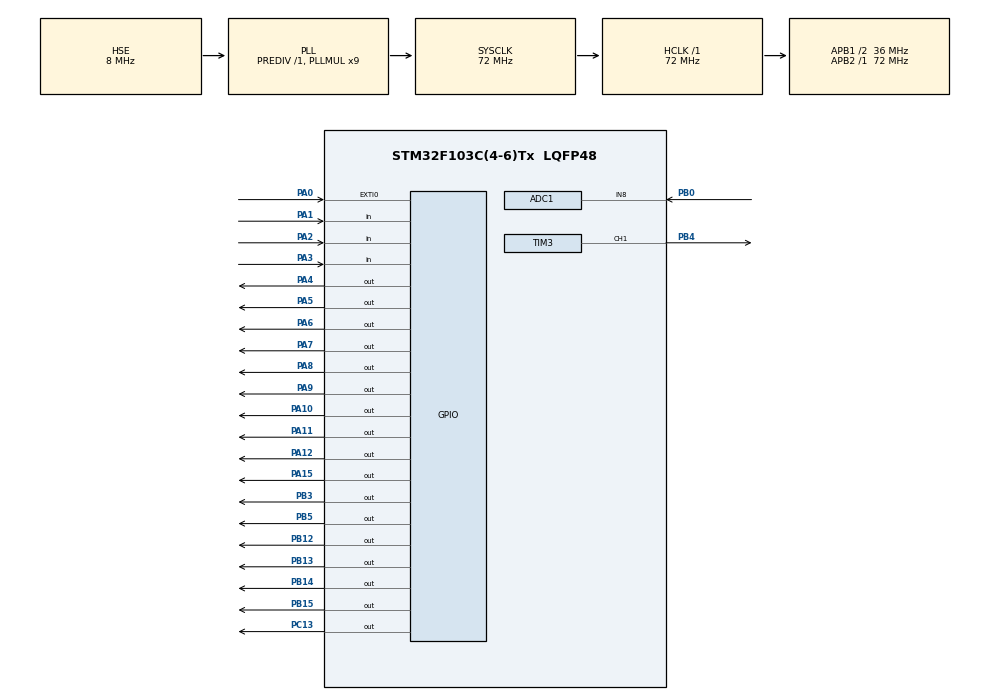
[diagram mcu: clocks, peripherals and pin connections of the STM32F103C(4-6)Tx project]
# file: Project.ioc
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ADC1.Channel-3\#ChannelRegularConversion=ADC_CHANNEL_8
ADC1.NbrOfConversionFlag=1
ADC1.Rank-3\#ChannelRegularConversion=1
ADC1.SamplingTime-3\#ChannelRegularConversion=ADC_SAMPLETIME_1CYCLE_5
ADC1.master=1
Mcu.Family=STM32F1
Mcu.Name=STM32F103C(4-6)Tx
Mcu.Package=LQFP48
NVIC.EXTI0_IRQn=true\:0\:0\:false\:false\:true\:true\:true
NVIC.PriorityGroup=NVIC_PRIORITYGROUP_4
NVIC.TIM1_UP_IRQn=true\:0\:0\:false\:false\:true\:true\:true
NVIC.TIM2_IRQn=true\:0\:0\:false\:false\:true\:true\:true
PA0-WKUP.GPIO_PuPd=GPIO_PULLUP
PA0-WKUP.Signal=GPXTI0
PA1.GPIO_PuPd=GPIO_PULLUP
PA1.Signal=GPIO_Input
PA10.Signal=GPIO_Output
PA11.Signal=GPIO_Output
PA12.Signal=GPIO_Output
PA13.Mode=Serial_Wire
PA13.Signal=SYS_JTMS-SWDIO
PA14.Mode=Serial_Wire
PA14.Signal=SYS_JTCK-SWCLK
PA15.Signal=GPIO_Output
PA2.GPIO_PuPd=GPIO_PULLUP
PA2.Signal=GPIO_Input
PA3.GPIO_PuPd=GPIO_PULLUP
PA3.Signal=GPIO_Input
PA4.GPIO_PuPd=GPIO_NOPULL
PA4.Signal=GPIO_Output
PA5.Signal=GPIO_Output
PA6.Signal=GPIO_Output
PA7.Signal=GPIO_Output
PA8.Signal=GPIO_Output
PA9.Signal=GPIO_Output
PB0.Signal=ADCx_IN8
PB12.Signal=GPIO_Output
PB13.Signal=GPIO_Output
PB14.Signal=GPIO_Output
PB15.Signal=GPIO_Output
PB3.Signal=GPIO_Output
PB4.Signal=S_TIM3_CH1
PB5.Signal=GPIO_Output
PC13-TAMPER-RTC.Signal=GPIO_Output
PD0-OSC_IN.Mode=HSE-External-Oscillator
PD0-OSC_IN.Signal=RCC_OSC_IN
PD1-OSC_OUT.Mode=HSE-External-Oscillator
PD1-OSC_OUT.Signal=RCC_OSC_OUT
ProjectManager.HeapSize=0x2000
ProjectManager.StackSize=0x2000
ProjectManager.TargetToolchain=EWARM V8.32
RCC.ADCPresc=RCC_ADCPCLK2_DIV6
RCC.AHBFreq_Value=72000000
RCC.APB1CLKDivider=RCC_HCLK_DIV2
RCC.APB1Freq_Value=36000000
RCC.APB1TimFreq_Value=72000000
RCC.APB2Freq_Value=72000000
RCC.APB2TimFreq_Value=72000000
RCC.HCLKFreq_Value=72000000
RCC.PLLMUL=RCC_PLL_MUL9
RCC.PLLSourceVirtual=RCC_PLLSOURCE_HSE
RCC.RCC_MCOSource=RCC_MCO1SOURCE_HSE
RCC.SYSCLKFreq_VALUE=72000000
RCC.SYSCLKSource=RCC_SYSCLKSOURCE_PLLCLK
RCC.USBFreq_Value=72000000
SH.ADCx_IN8.0=ADC1_IN8,IN8
SH.S_TIM3_CH1.0=TIM3_CH1,PWM Generation1 CH1
TIM1.Period=9
TIM1.Prescaler=7199
TIM2.Period=9
TIM2.Prescaler=7199
TIM3.Channel-PWM\ Generation1\ CH1=TIM_CHANNEL_1
TIM3.Period=50000
TIM3.Prescaler=499
VP_TIM1_VS_ClockSourceINT.Mode=Internal
VP_TIM2_VS_ClockSourceINT.Mode=Internal
board=custom

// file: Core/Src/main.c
/* USER CODE BEGIN Header */
/**
 ******************************************************************************
 * @file           : main.c
 * @brief          : Main program body
 ******************************************************************************
 * @attention
 *
 * <h2><center>&copy; Copyright (c) 2022 STMicroelectronics.
 * All rights reserved.</center></h2>
 *
 * This software component is licensed by ST under BSD 3-Clause license,
 * the "License"; You may not use this file except in compliance with the
 * License. You may obtain a copy of the License at:
 *                        opensource.org/licenses/BSD-3-Clause
 *
 ******************************************************************************
 */
/* USER CODE END Header */
#include "main.h"

/* USER CODE BEGIN Includes */
#include "logic.h"
/* USER CODE END Includes */

ADC_HandleTypeDef hadc1;

TIM_HandleTypeDef htim1;
TIM_HandleTypeDef htim2;
TIM_HandleTypeDef htim3;

void SystemClock_Config(void);
static void MX_GPIO_Init(void);
static void MX_TIM2_Init(void);
static void MX_TIM3_Init(void);
static void MX_TIM1_Init(void);
static void MX_ADC1_Init(void);

int main(void)
{

  /* MCU Configuration--------------------------------------------------------*/

  /* Reset of all peripherals, Initializes the Flash interface and the Systick. */
  HAL_Init();

  /* Configure the system clock */
  SystemClock_Config();

  /* Initialize all configured peripherals */
  MX_GPIO_Init();
  MX_TIM2_Init();
  MX_TIM3_Init();
  MX_TIM1_Init();
  MX_ADC1_Init();
  /* USER CODE BEGIN 2 */
  init();
  /* USER CODE END 2 */

  /* Infinite loop */
  /* USER CODE BEGIN WHILE */
  while (1)
  {
    loop();
    /* USER CODE END WHILE */

  }
}

void SystemClock_Config(void)
{
  RCC_OscInitTypeDef RCC_OscInitStruct = {0};
  RCC_ClkInitTypeDef RCC_ClkInitStruct = {0};
  RCC_PeriphCLKInitTypeDef PeriphClkInit = {0};

  /** Initializes the RCC Oscillators according to the specified parameters
   * in the RCC_OscInitTypeDef structure.
   */
  RCC_OscInitStruct.OscillatorType = RCC_OSCILLATORTYPE_HSE;
  RCC_OscInitStruct.HSEState = RCC_HSE_ON;
  RCC_OscInitStruct.HSEPredivValue = RCC_HSE_PREDIV_DIV1;
  RCC_OscInitStruct.HSIState = RCC_HSI_ON;
  RCC_OscInitStruct.PLL.PLLState = RCC_PLL_ON;
  RCC_OscInitStruct.PLL.PLLSource = RCC_PLLSOURCE_HSE;
  RCC_OscInitStruct.PLL.PLLMUL = RCC_PLL_MUL9;
  if (HAL_RCC_OscConfig(&RCC_OscInitStruct) != HAL_OK)
  {
    Error_Handler();
  }
  /** Initializes the CPU, AHB and APB buses clocks
   */
  RCC_ClkInitStruct.ClockType = RCC_CLOCKTYPE_HCLK | RCC_CLOCKTYPE_SYSCLK | RCC_CLOCKTYPE_PCLK1 | RCC_CLOCKTYPE_PCLK2;
  RCC_ClkInitStruct.SYSCLKSource = RCC_SYSCLKSOURCE_PLLCLK;
  RCC_ClkInitStruct.AHBCLKDivider = RCC_SYSCLK_DIV1;
  RCC_ClkInitStruct.APB1CLKDivider = RCC_HCLK_DIV2;
  RCC_ClkInitStruct.APB2CLKDivider = RCC_HCLK_DIV1;

  if (HAL_RCC_ClockConfig(&RCC_ClkInitStruct, FLASH_LATENCY_2) != HAL_OK)
  {
    Error_Handler();
  }
  PeriphClkInit.PeriphClockSelection = RCC_PERIPHCLK_ADC;
  PeriphClkInit.AdcClockSelection = RCC_ADCPCLK2_DIV6;
  if (HAL_RCCEx_PeriphCLKConfig(&PeriphClkInit) != HAL_OK)
  {
    Error_Handler();
  }
}

static void MX_ADC1_Init(void)
{

  ADC_ChannelConfTypeDef sConfig = {0};

  /** Common config
   */
  hadc1.Instance = ADC1;
  hadc1.Init.ScanConvMode = ADC_SCAN_DISABLE;
  hadc1.Init.ContinuousConvMode = DISABLE;
  hadc1.Init.DiscontinuousConvMode = DISABLE;
  hadc1.Init.ExternalTrigConv = ADC_SOFTWARE_START;
  hadc1.Init.DataAlign = ADC_DATAALIGN_RIGHT;
  hadc1.Init.NbrOfConversion = 1;
  if (HAL_ADC_Init(&hadc1) != HAL_OK)
  {
    Error_Handler();
  }
  /** Configure Regular Channel
   */
  sConfig.Channel = ADC_CHANNEL_8;
  sConfig.Rank = ADC_REGULAR_RANK_1;
  sConfig.SamplingTime = ADC_SAMPLETIME_1CYCLE_5;
  if (HAL_ADC_ConfigChannel(&hadc1, &sConfig) != HAL_OK)
  {
    Error_Handler();
  }
}

static void MX_TIM1_Init(void)
{

  TIM_ClockConfigTypeDef sClockSourceConfig = {0};
  TIM_MasterConfigTypeDef sMasterConfig = {0};

  htim1.Instance = TIM1;
  htim1.Init.Prescaler = 7199;
  htim1.Init.CounterMode = TIM_COUNTERMODE_UP;
  htim1.Init.Period = 9;
  htim1.Init.ClockDivision = TIM_CLOCKDIVISION_DIV1;
  htim1.Init.RepetitionCounter = 0;
  htim1.Init.AutoReloadPreload = TIM_AUTORELOAD_PRELOAD_DISABLE;
  if (HAL_TIM_Base_Init(&htim1) != HAL_OK)
  {
    Error_Handler();
  }
  sClockSourceConfig.ClockSource = TIM_CLOCKSOURCE_INTERNAL;
  if (HAL_TIM_ConfigClockSource(&htim1, &sClockSourceConfig) != HAL_OK)
  {
    Error_Handler();
  }
  sMasterConfig.MasterOutputTrigger = TIM_TRGO_RESET;
  sMasterConfig.MasterSlaveMode = TIM_MASTERSLAVEMODE_DISABLE;
  if (HAL_TIMEx_MasterConfigSynchronization(&htim1, &sMasterConfig) != HAL_OK)
  {
    Error_Handler();
  }
}

static void MX_TIM2_Init(void)
{

  TIM_ClockConfigTypeDef sClockSourceConfig = {0};
  TIM_MasterConfigTypeDef sMasterConfig = {0};

  htim2.Instance = TIM2;
  htim2.Init.Prescaler = 7199;
  htim2.Init.CounterMode = TIM_COUNTERMODE_UP;
  htim2.Init.Period = 9;
  htim2.Init.ClockDivision = TIM_CLOCKDIVISION_DIV1;
  htim2.Init.AutoReloadPreload = TIM_AUTORELOAD_PRELOAD_DISABLE;
  if (HAL_TIM_Base_Init(&htim2) != HAL_OK)
  {
    Error_Handler();
  }
  sClockSourceConfig.ClockSource = TIM_CLOCKSOURCE_INTERNAL;
  if (HAL_TIM_ConfigClockSource(&htim2, &sClockSourceConfig) != HAL_OK)
  {
    Error_Handler();
  }
  sMasterConfig.MasterOutputTrigger = TIM_TRGO_RESET;
  sMasterConfig.MasterSlaveMode = TIM_MASTERSLAVEMODE_DISABLE;
  if (HAL_TIMEx_MasterConfigSynchronization(&htim2, &sMasterConfig) != HAL_OK)
  {
    Error_Handler();
  }
}

static void MX_TIM3_Init(void)
{

  TIM_MasterConfigTypeDef sMasterConfig = {0};
  TIM_OC_InitTypeDef sConfigOC = {0};

  /* USER CODE BEGIN TIM3_Init 1 */
  // 250�� * 500(0-499) = 125���
  // 72000000/576 = 125000
  // Pre = 499
  // Per = 99

  // 1800 //2879
  // 100
  /* USER CODE END TIM3_Init 1 */
  htim3.Instance = TIM3;
  htim3.Init.Prescaler = 499;
  htim3.Init.CounterMode = TIM_COUNTERMODE_UP;
  htim3.Init.Period = 99;
  htim3.Init.ClockDivision = TIM_CLOCKDIVISION_DIV1;
  htim3.Init.AutoReloadPreload = TIM_AUTORELOAD_PRELOAD_DISABLE;
  if (HAL_TIM_PWM_Init(&htim3) != HAL_OK)
  {
    Error_Handler();
  }
  sMasterConfig.MasterOutputTrigger = TIM_TRGO_RESET;
  sMasterConfig.MasterSlaveMode = TIM_MASTERSLAVEMODE_DISABLE;
  if (HAL_TIMEx_MasterConfigSynchronization(&htim3, &sMasterConfig) != HAL_OK)
  {
    Error_Handler();
  }
  sConfigOC.OCMode = TIM_OCMODE_PWM1;
  sConfigOC.Pulse = 0;
  sConfigOC.OCPolarity = TIM_OCPOLARITY_HIGH;
  sConfigOC.OCFastMode = TIM_OCFAST_DISABLE;
  if (HAL_TIM_PWM_ConfigChannel(&htim3, &sConfigOC, TIM_CHANNEL_1) != HAL_OK)
  {
    Error_Handler();
  }
  HAL_TIM_MspPostInit(&htim3);
}

static void MX_GPIO_Init(void)
{
  GPIO_InitTypeDef GPIO_InitStruct = {0};

  /* GPIO Ports Clock Enable */
  __HAL_RCC_GPIOC_CLK_ENABLE();
  __HAL_RCC_GPIOD_CLK_ENABLE();
  __HAL_RCC_GPIOA_CLK_ENABLE();
  __HAL_RCC_GPIOB_CLK_ENABLE();

  /*Configure GPIO pin Output Level */
  HAL_GPIO_WritePin(GPIOC, GPIO_PIN_13, GPIO_PIN_RESET);

  /*Configure GPIO pin Output Level */
  HAL_GPIO_WritePin(GPIOA, GPIO_PIN_4 | GPIO_PIN_5 | GPIO_PIN_6 | GPIO_PIN_7 | GPIO_PIN_8 | GPIO_PIN_9 | GPIO_PIN_10 | GPIO_PIN_11 | GPIO_PIN_12 | GPIO_PIN_15, GPIO_PIN_RESET);

  /*Configure GPIO pin Output Level */
  HAL_GPIO_WritePin(GPIOB, GPIO_PIN_12 | GPIO_PIN_13 | GPIO_PIN_14 | GPIO_PIN_15 | GPIO_PIN_3 | GPIO_PIN_5, GPIO_PIN_RESET);

  /*Configure GPIO pin : PC13 */
  GPIO_InitStruct.Pin = GPIO_PIN_13;
  GPIO_InitStruct.Mode = GPIO_MODE_OUTPUT_PP;
  GPIO_InitStruct.Pull = GPIO_NOPULL;
  GPIO_InitStruct.Speed = GPIO_SPEED_FREQ_LOW;
  HAL_GPIO_Init(GPIOC, &GPIO_InitStruct);

  /*Configure GPIO pin : PA0 */
  GPIO_InitStruct.Pin = GPIO_PIN_0;
  GPIO_InitStruct.Mode = GPIO_MODE_IT_RISING;
  GPIO_InitStruct.Pull = GPIO_PULLUP;
  HAL_GPIO_Init(GPIOA, &GPIO_InitStruct);

  /*Configure GPIO pins : PA1 PA2 PA3 */
  GPIO_InitStruct.Pin = GPIO_PIN_1 | GPIO_PIN_2 | GPIO_PIN_3;
  GPIO_InitStruct.Mode = GPIO_MODE_INPUT;
  GPIO_InitStruct.Pull = GPIO_PULLUP;
  HAL_GPIO_Init(GPIOA, &GPIO_InitStruct);

  /*Configure GPIO pins : PA4 PA5 PA6 PA7
                           PA8 PA9 PA10 PA11
                           PA12 PA15 */
  GPIO_InitStruct.Pin = GPIO_PIN_4 | GPIO_PIN_5 | GPIO_PIN_6 | GPIO_PIN_7 | GPIO_PIN_8 | GPIO_PIN_9 | GPIO_PIN_10 | GPIO_PIN_11 | GPIO_PIN_12 | GPIO_PIN_15;
  GPIO_InitStruct.Mode = GPIO_MODE_OUTPUT_PP;
  GPIO_InitStruct.Pull = GPIO_NOPULL;
  GPIO_InitStruct.Speed = GPIO_SPEED_FREQ_LOW;
  HAL_GPIO_Init(GPIOA, &GPIO_InitStruct);

  /*Configure GPIO pins : PB12 PB13 PB14 PB15
                           PB3 PB5 */
  GPIO_InitStruct.Pin = GPIO_PIN_12 | GPIO_PIN_13 | GPIO_PIN_14 | GPIO_PIN_15 | GPIO_PIN_3 | GPIO_PIN_5;
  GPIO_InitStruct.Mode = GPIO_MODE_OUTPUT_PP;
  GPIO_InitStruct.Pull = GPIO_NOPULL;
  GPIO_InitStruct.Speed = GPIO_SPEED_FREQ_LOW;
  HAL_GPIO_Init(GPIOB, &GPIO_InitStruct);

  /* EXTI interrupt init*/
  HAL_NVIC_SetPriority(EXTI0_IRQn, 0, 0);
  HAL_NVIC_EnableIRQ(EXTI0_IRQn);
}

void Error_Handler(void)
{
  __disable_irq();
  while (1)
  {
  }
}

/************************ (C) COPYRIGHT STMicroelectronics *****END OF FILE****/
